# DA14682 register map
Vendor: Dialog; Series: DA14682; File version: 1.2
CPU: CM0 r1p0, little endian, MPU, FPU, 3 interrupt priority bits
Registers are 16-bit, read-write, reset 0x0 unless marked. A register's access mark holds for its fields unless they carry their own. Offsets are from the block's base; [hi:lo] are bit positions.

## CRG_TOP — CRG_TOP registers
Base 0x50000000
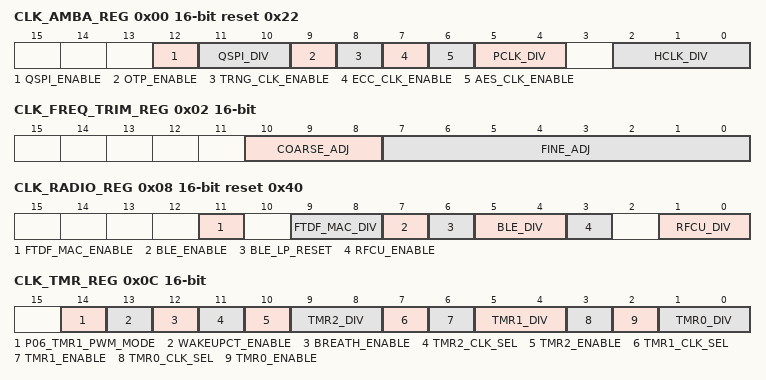
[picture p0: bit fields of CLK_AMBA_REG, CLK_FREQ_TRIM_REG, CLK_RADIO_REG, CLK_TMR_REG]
0x00 CLK_AMBA_REG reset 0x22 — HCLK, PCLK, divider and clock gates
  [12] QSPI_ENABLE — Clock enable for QSPI controller
  [11:10] QSPI_DIV — QSPI divider 00 = divide by 1 01 = divide by 2 10 = divide by 4 11 = divide by 8
  [9] OTP_ENABLE — Clock enable for OTP controller
  [8] TRNG_CLK_ENABLE — Clock enable for TRNG block
  [7] ECC_CLK_ENABLE — Clock enable for ECC block
  [6] AES_CLK_ENABLE — Clock enable for AES crypto block
  [5:4] PCLK_DIV — APB interface clock, Cascaded with HCLK: 00 = divide hclk by 1 01 = divide hclk by 2 10 = divide hclk by 4 11 = divide hclk by 8
  [2:0] HCLK_DIV — AHB interface and microprocessor clock. Source clock divided by: 000 = divide hclk by 1 001 = divide hclk by 2 010 = divide hclk by 4 011 = divide hclk by 8 1xx = divide hclk by 16
0x02 CLK_FREQ_TRIM_REG — Xtal frequency trimming register.
  [10:8] COARSE_ADJ — Xtal frequency course trimming register. 0x0 = lowest frequency 0x7 = highest frequencyIncrement or decrement the binary value with 1. Wait approximately 200usec to allow the adjustment to settle.
  [7:0] FINE_ADJ — Xtal frequency fine trimming register.0x00 = lowest frequency 0xFF = highest frequency
0x08 CLK_RADIO_REG reset 0x40 — Radio PLL control register
  [11] FTDF_MAC_ENABLE — Enable the FTDF MAC core clocks
  [9:8] FTDF_MAC_DIV — Division factor for FTCF MAC clock, relative to the DIVN clock 00 = Divide by 1 01 = Divide by 2 10 = Divide by 4 11 = Divide by 8 It should always be set to 00.
  [7] BLE_ENABLE — Enable the BLE core clocks. When the BLE system clock is disabled, either due to the CLK_RADIO_REG[BLE_ENABLE] or due to the PMU_CTRL_REG[BLE_SLEEP], then any access to the BLE Register file will issue a hard fault to the CPU.
  [6] BLE_LP_RESET — Reset for the BLE LP timer
  [5:4] BLE_DIV — Division factor for BLE core blocks, having as reference the DIVN clock: 00 = Divide by 1 01 = Divide by 2 10 = Divide by 4 11 = Divide by 8 The programmed frequency should not be lower than 8MHz, not faster than 16MHz and not faster than the programmed CPU clock frequency. Refer also to BLE_CNTL2_REG[BLE_CLK_SEL].
  [3] RFCU_ENABLE — Enable the RF control Unit clock
  [1:0] RFCU_DIV — Division factor for RF Control Unit 0x0 = divide by 1 0x1 = divide by 2 0x2 = divide by 4 0x3 = divide by 8 The programmed frequency must be exactly 8MHz.
0x0C CLK_TMR_REG — Clock control for the timers
  [14] P06_TMR1_PWM_MODE — Maps Timer1_pwm onto P06, when DEBUGGER_EN = '0'. This state is preserved during deep sleep, to allow PWM output on the pad during deep sleep.
  [13] WAKEUPCT_ENABLE — Enables the clock
  [12] BREATH_ENABLE — Enables the clock
  [11] TMR2_CLK_SEL — Selects the clock source 1 = DIV1 clock 0 = DIVN clock
  [10] TMR2_ENABLE — Enable timer clock
  [9:8] TMR2_DIV — Division factor for Timer 0x0 = divide by 1 0x1 = divide by 2 0x2 = divide by 4 0x3 = divide by 8
  [7] TMR1_CLK_SEL — Selects the clock source 1 = DIV1 clock 0 = DIVN clock
  [6] TMR1_ENABLE — Enable timer clock
  [5:4] TMR1_DIV — Division factor for Timer 0x0 = divide by 1 0x1 = divide by 2 0x2 = divide by 4 0x3 = divide by 8
  [3] TMR0_CLK_SEL — Selects the clock source 1 = DIV1 clock 0 = DIVN clock
  [2] TMR0_ENABLE — Enable timer clock
  [1:0] TMR0_DIV — Division factor for Timer 0x0 = divide by 1 0x1 = divide by 2 0x2 = divide by 4 0x3 = divide by 8
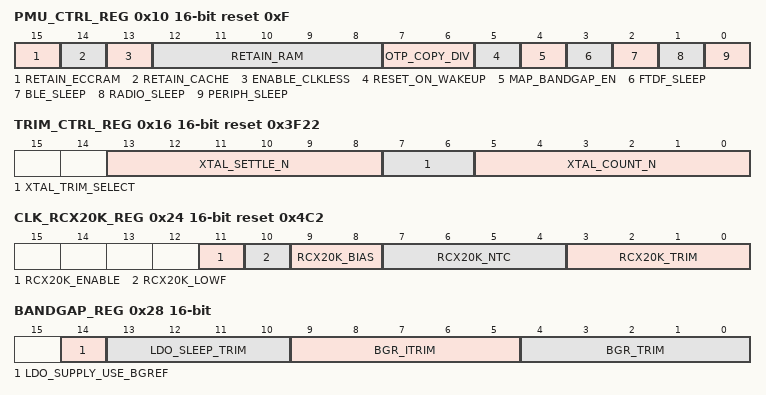
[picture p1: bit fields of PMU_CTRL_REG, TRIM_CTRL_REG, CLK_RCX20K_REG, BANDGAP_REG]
0x10 PMU_CTRL_REG reset 0xF — Power Management Unit control register
  [15] RETAIN_ECCRAM — Selects the retainability of the ECC u-Code RAM during deep sleep. '1' is retainable, '0' is power gated
  [14] RETAIN_CACHE — Selects the retainability of the cache block during deep sleep. '1' is retainable, '0' is power gated
  [13] ENABLE_CLKLESS — Selects the clockless sleep mode. Wakeup is done asynchronously. When set to '1', the lp_clk is stopped during deep sleep, until a wakeup event (not debounced) is detected by the WAKUPCT block. When set to '0', the lp_clk continues running, so the MAC counters keep on running. This mode cannot be combined with regulated sleep, so keep SLEEP_TIMER=0 when using ENABLE_CLKLESS.
  [12:8] RETAIN_RAM — Select the retainability of the 5 system memory RAM macros during deep sleep. '1' is retainable, '0' is power gated (4) is SYSRAM5 (3) is SYSRAM4 (2) is SYSRAM3 (1) is SYSRAM2 (0) is SYSRAM1
  [7:6] OTP_COPY_DIV — Sets the HCLK division during OTP mirroring
  [5] RESET_ON_WAKEUP — Perform a Hardware Reset after waking up. Booter will be started.
  [4] MAP_BANDGAP_EN — Maps the bandgap_enable to P06
  [3] FTDF_SLEEP — Put the FTDF in powerdown
  [2] BLE_SLEEP — Put the BLE in powerdown. When the BLE system clock is disabled, either due to the CLK_RADIO_REG[BLE_ENABLE] or due to the PMU_CTRL_REG[BLE_SLEEP], then any access to the BLE Register file will issue a hard fault to the CPU.
  [1] RADIO_SLEEP — Put the digital part of the radio in powerdown
  [0] PERIPH_SLEEP — Put all peripherals (I2C, UART, SPI, ADC) in powerdown
0x16 TRIM_CTRL_REG reset 0x3F22 — Control trimming of the XTAL16M
  [13:8] XTAL_SETTLE_N — Designates that the XTAL16 can be safely used as the CPU clock. When XTAL16_CLK_CNT reases this value, the signal XTAL_SETTLE_READY will be set
  [7:6] XTAL_TRIM_SELECT — Select which source controls the XTAL trimming 0b00: xtal counter. Starts XTAL16M_START_REG, after COUNT_N * 32 xtal pulses trim is changed to CLK_FREQ_TRIM_REG. 0b01: xtal OK filter. Starts with XTAL16M_START_REG, when xtal is ramping is changed to CLK_FREQ_TRIM_REG 0b10: statically forced off. Only uses CLK_FREQ_TRIM_REG. 0b11: xtal OK filter, 2 stage. Starts with XTAL16M_START_REG switches to XTAL16M_RAMP_REG when sw1='1', and switches to CLK_FREQ_TRIM_REG when sw2='1'.
  [5:0] XTAL_COUNT_N — Defines the number of XTAL cycles to be counted, before the xtal trimming is applied, in steps of 32. 0x01: 32 0x02: 64 0x3f:2016
0x24 CLK_RCX20K_REG reset 0x4C2 — RCX-oscillator control register
  [11] RCX20K_ENABLE — Enable the RCX oscillator
  [10] RCX20K_LOWF — Extra low frequency
  [9:8] RCX20K_BIAS — Bias control
  [7:4] RCX20K_NTC — Temperature control
  [3:0] RCX20K_TRIM — 0000 = lowest frequency 0111 = default 1111 = highest frequency
0x28 BANDGAP_REG — bandgap trimming
  [14] LDO_SUPPLY_USE_BGREF — 0x0 -> LDO_SUPPLY_(VBAT/USB) uses V12 voltage/(V12/2Mohm) current as reference 0x1 -> LDO_SUPPLY_(VBAT/USB) uses bandgap voltage/bandgap current (1uA) as reference -> set 0x1 in (booter-)software Switch to 0x1 at start of user application when maximum BOD functionality is switched on.
  [13:10] LDO_SLEEP_TRIM — 0x4 --> 1120 mV 0x5 --> 1089 mV 0x6 --> 1058 mV 0x7 --> 1030 mV 0x0 --> 1037 mV 0x1 --> 1005 mV 0x2 --> 978 mV 0x3 --> 946 mV 0x8 --> 952 mV 0x9 --> 918 mV 0xA --> 889 mV 0xB --> 861 mV 0xC --> 862 mV 0xD --> 828 mV 0xE --> 798 mV 0xF --> 770 mV These values are from simulation and vary over corners
  [9:5] BGR_ITRIM — Current trimming for bias
  [4:0] BGR_TRIM — Trim register for bandgap
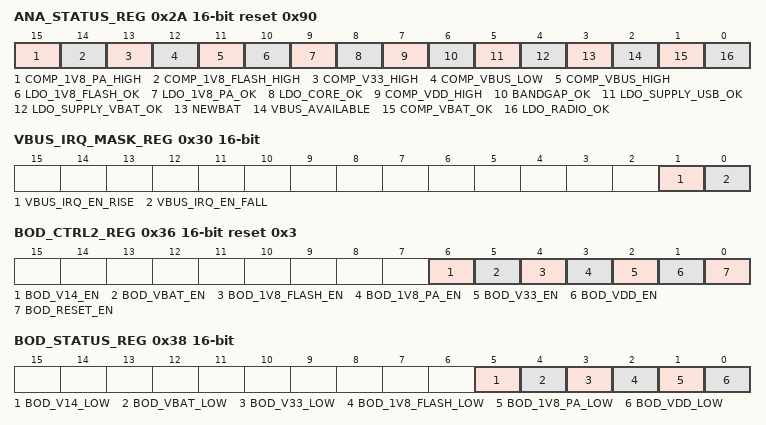
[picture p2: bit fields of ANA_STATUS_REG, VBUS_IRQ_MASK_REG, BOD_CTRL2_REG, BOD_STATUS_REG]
0x2A ANA_STATUS_REG reset 0x90 — status bit of analog (power management) circuits
  [15] COMP_1V8_PA_HIGH ro — VDD1V8P > 1.7V
  [14] COMP_1V8_FLASH_HIGH ro — VDD1V8 > 1.7V
  [13] COMP_V33_HIGH ro — V33 > 1.7V
  [12] COMP_VBUS_LOW ro — VBUS > 3.4V
  [11] COMP_VBUS_HIGH ro — VBUS > 4V
  [10] LDO_1V8_FLASH_OK ro — ldo_vdd1v8 = ok
  [9] LDO_1V8_PA_OK ro — ldo_vdd1v8P = ok
  [8] LDO_CORE_OK ro
  [7] COMP_VDD_HIGH ro — VDD > 1.13V
  [6] BANDGAP_OK ro
  [5] LDO_SUPPLY_USB_OK ro
  [4] LDO_SUPPLY_VBAT_OK ro
  [3] NEWBAT ro — new battery has been detected
  [2] VBUS_AVAILABLE ro — vbus is available (vbus > vbat)
  [1] COMP_VBAT_OK ro — vbat > 1.7V
  [0] LDO_RADIO_OK ro
0x30 VBUS_IRQ_MASK_REG — IRQ masking
  [1] VBUS_IRQ_EN_RISE — Setting this bit to '1' enables VBUS_IRQ generation when the VBUS starts to ramp above threshold
  [0] VBUS_IRQ_EN_FALL — Setting this bit to '1' enables VBUS_IRQ generation when the VBUS starts to fall below threshold
0x32 VBUS_IRQ_CLEAR_REG — Clear pending IRQ register
  [15:0] VBUS_IRQ_CLEAR wo — Writing any value to this register will reset the VBUS_IRQ line
0x36 BOD_CTRL2_REG reset 0x3 — Brown Out Detection control register
  [6] BOD_V14_EN — V14 BOD Enable
  [5] BOD_VBAT_EN — VBAT BOD Enable
  [4] BOD_1V8_FLASH_EN — 1V8 Flash BOD Enable
  [3] BOD_1V8_PA_EN — 1V8 PA BOD Enable
  [2] BOD_V33_EN — V33 BOD Enable
  [1] BOD_VDD_EN — VDD BOD Enable
  [0] BOD_RESET_EN — Generate a chip reset on BOD event
0x38 BOD_STATUS_REG — Brown Out Detection status register
  [5] BOD_V14_LOW ro — Indicates V14 > V14_Trigger
  [4] BOD_VBAT_LOW ro — Indicates VBAT > VBAT_Trigger
  [3] BOD_V33_LOW ro — Indicates V33 > V33_Trigger
  [2] BOD_1V8_FLASH_LOW ro — Indicates V18_Flash > V18_Flash_Trigger
  [1] BOD_1V8_PA_LOW ro — Indicates V18_PA > V18_PA_Trigger
  [0] BOD_VDD_LOW ro — Indicates VDD > VDD_Trigger
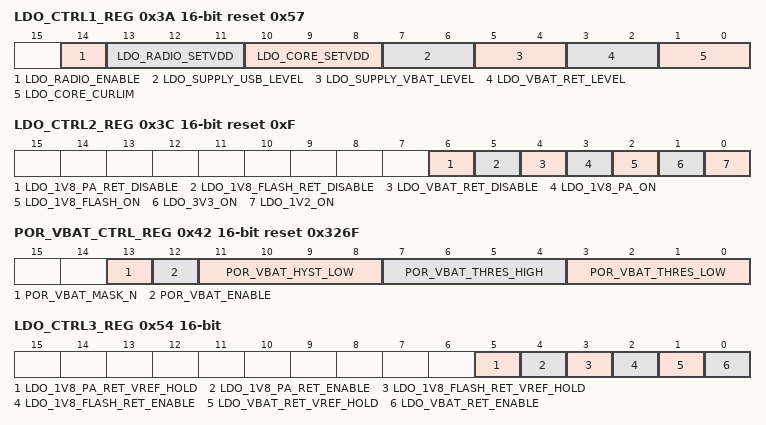
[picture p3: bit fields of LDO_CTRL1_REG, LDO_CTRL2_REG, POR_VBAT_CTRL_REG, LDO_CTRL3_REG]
0x3A LDO_CTRL1_REG reset 0x57 — LDO control register
  [14] LDO_RADIO_ENABLE — Enables (1) or disables (0) LDO_RADIO For fast XTAL startup, this bit may be kept to '1' during deep sleep. The LDO is switched off automatically when in deep sleep, and enabled when waking up.
  [13:11] LDO_RADIO_SETVDD — Sets the output voltage of LDO_RADIO 000 = 1.30 V 001 = 1.35 V 010 = 1.40 V 011 = 1.45 V 1XX = 1.50 V
  [10:8] LDO_CORE_SETVDD — Sets the output voltage of LDO_CORE 000 = 1.20 V 001 = 1.15 V 010 = 1.10 V 011 = 1.05 V 1XX = 1.32 V
  [7:6] LDO_SUPPLY_USB_LEVEL — Sets the output voltage of LDO_SUPPLY_USB 00 = 2.40 V 01 = 3.30 V 10 = 3.45 V 11 = 3.00 V
  [5:4] LDO_SUPPLY_VBAT_LEVEL — Sets the output voltage of LDO_SUPPLY_VBAT 00 = 2.40 V 01 = 3.30 V 10 = 3.45 V 11 = 3.00 V
  [3:2] LDO_VBAT_RET_LEVEL — Sets the output voltage of LDO_VBAT_RET 00 = 2.40 V 01 = 3.30 V 10 = 3.45 V 11 = 3.00 V
  [1:0] LDO_CORE_CURLIM — Sets the current limit of LDO_CORE 00 = Current limiter disabled 01 = 8 mA 10 = 60 mA 11 = 80 mA
0x3C LDO_CTRL2_REG reset 0xF — LDO control register
  [6] LDO_1V8_PA_RET_DISABLE — Disables (1) or enables (0) LDO_1V8_PA_RET
  [5] LDO_1V8_FLASH_RET_DISABLE — Disables (1) or enables (0) LDO_1V8_FLASH_RET
  [4] LDO_VBAT_RET_DISABLE — Disables (1) or enables (0) LDO_VBAT_RET
  [3] LDO_1V8_PA_ON — Enables (1) or disables (0) LDO_1V8_PA
  [2] LDO_1V8_FLASH_ON — Enables (1) or disables (0) LDO_1V8_FLASH
  [1] LDO_3V3_ON — Enables (1) or disables (0) LDO_SUPPLY_VBAT and LDO_SUPPLY_USB
  [0] LDO_1V2_ON — Enables (1) or disables (0) LDO_CORE
0x3E SLEEP_TIMER_REG — Timer for regulated sleep
  [15:0] SLEEP_TIMER — Defines the amount of ticks of the sleep clock between enabling the bandgap for re-charging the retention LDOs. This value depends on the load and should be calibrated on a per application basis.If set to 0, no recharging cycle will happen at all. Keep this value to 0 (no recharging) when using the clockless sleep.
0x42 POR_VBAT_CTRL_REG reset 0x326F — Controls the POR on VBAT
  [13] POR_VBAT_MASK_N — Enables propagation of the generated POR
  [12] POR_VBAT_ENABLE — Enables generation of the POR
  [11:8] POR_VBAT_HYST_LOW — Controls hysteresis of POR (20mV/LSB) - Set to 0x0 when non-reset settings are used for POR_VBAT_THRES_LOW and POR_VBAT_THRES_HIGH.
  [7:4] POR_VBAT_THRES_HIGH — High-side (PTAT) threshold contribution - Align setting with POR_VBAT_THRES_LOW. Set POR_VBAT_HYST_LOW to 0x0, when non-reset settings are used. Threshold --> Setting 1.25V --> 0x0 1.27V --> 0x1 1.29V --> 0x2 1.31V --> 0x3 1.44V --> 0x4 1.49V --> 0x5 1.53V --> 0x6 --> RESET 1.58V --> 0x7 1.63V --> 0x8 1.68V --> 0x9 1.73V --> 0xA 1.78V --> 0xB 1.83V --> 0xC 1.87V --> 0xD 1.92V --> 0xE 1.97V --> 0xF
  [3:0] POR_VBAT_THRES_LOW — Low-side (CTAT) threshold contribution - Align setting with POR_VBAT_THRES_HIGH. Set POR_VBAT_HYST_LOW to 0x0, when non-reset settings are used. Threshold --> Setting 1.25V --> 0xC 1.27V --> 0xC 1.29V --> 0xC 1.31V --> 0xC 1.44V --> 0x0 1.49V --> 0x1 1.53V --> 0x2 1.58V --> 0x3 1.63V --> 0x4 1.68V --> 0x5 1.73V --> 0x6 1.78V --> 0x7 1.83V --> 0x8 1.87V --> 0x9 1.92V --> 0xA 1.97V --> 0xB 1.63V -- > 0xF; Reset mode - use only with POR_VBAT_THRES_HIGH=0x6 and POR_VBAT_THRES_HYST=0x2
0x50 XTALRDY_CTRL_REG — Control register for XTALRDY IRQ
  [7:0] XTALRDY_CNT — Number of LP cycles between the crystal is enabled, and the XTALRDY_IRQ is fired. 0x00: no interrupt
0x54 LDO_CTRL3_REG — Retention LDO control register
  [5] LDO_1V8_PA_RET_VREF_HOLD — Setting of this register is "ORed" with the vref_hold control from the CRG StateMachine. "0" = CRG controls the T&H of Vref. "1" = T&H is always in "Hold"
  [4] LDO_1V8_PA_RET_ENABLE — Setting of this register is "ORed" with the ldo_enable control from the CRG StateMachine. "0" = CRG controls the enable of the LDO. "1" = LDO is always enabled To activate a retention LDO in "active-mode", this bit must be "1" and the VREF_HOLD bit must be "0".
  [3] LDO_1V8_FLASH_RET_VREF_HOLD — Setting of this register is "ORed" with the vref_hold control from the CRG StateMachine. "0" = CRG controls the T&H of Vref. "1" = T&H is always in "Hold"
  [2] LDO_1V8_FLASH_RET_ENABLE — Setting of this register is "ORed" with the ldo_enable control from the CRG StateMachine. "0" = CRG controls the enable of the LDO. "1" = LDO is always enabled To activate a retention LDO in "active-mode", this bit must be "1" and the VREF_HOLD bit must be "0".
  [1] LDO_VBAT_RET_VREF_HOLD — Setting of this register is "ORed" with the vref_hold control from the CRG StateMachine. "0" = CRG controls the T&H of Vref. "1" = T&H is always in "Hold"
  [0] LDO_VBAT_RET_ENABLE — Setting of this register is "ORed" with the ldo_enable control from the CRG StateMachine. "0" = CRG controls the enable of the LDO. "1" = LDO is always enabled To activate a retention LDO in "active-mode", this bit must be "1" and the VREF_HOLD bit must be "0".
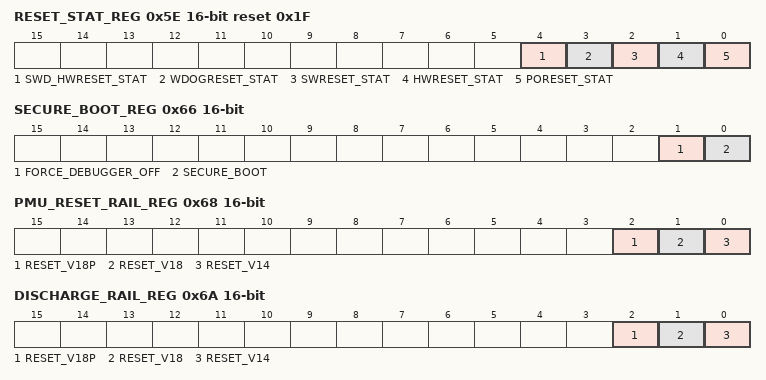
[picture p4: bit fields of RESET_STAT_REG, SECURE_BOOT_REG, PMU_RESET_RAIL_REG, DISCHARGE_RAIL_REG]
0x5E RESET_STAT_REG reset 0x1F — Reset status register
  [4] SWD_HWRESET_STAT — Indicates that a write to SWD_RESET_REG has happened. Note thatit is also set when a POReset has happened.
  [3] WDOGRESET_STAT — Indicates that a Watchdog has happened. Note that it is also set when a POReset has happened.
  [2] SWRESET_STAT — Indicates that a SW Reset has happened
  [1] HWRESET_STAT — Indicates that a HW Reset has happened
  [0] PORESET_STAT — Indicates that a PowerOn Reset has happened
0x66 SECURE_BOOT_REG — Controls secure booting
  [1] FORCE_DEBUGGER_OFF — Follows the respective OTP flag value. Is write-one-only and will be reset by POR only! Its value is updated by the BootROM code. 1: The system debugger SWD is totally disabled. 0: The system debugger is enabled with DEBUGGER_ENABLE
  [0] SECURE_BOOT — Follows the respective OTP flag value. Is write-one-only and will be reset by POR only! Its value is updated by the BootROM code. 1: system is a secure system supporting secure boot 0: system is not supporting secure boot
0x68 PMU_RESET_RAIL_REG — Controls rail resetting when RST is pulsed
  [2] RESET_V18P — 1: Enables discharging of the V18P rail when HW reset is pressed 0: this rail will not be discharged when HW reset is pressed
  [1] RESET_V18 — 1: Enables discharging of the V18 rail when HW reset is pressed 0: this rail will not be discharged when HW reset is pressed
  [0] RESET_V14 — 1: Enables discharging of the V14 rail when HW reset is pressed 0: this rail will not be discharged when HW reset is pressed
0x6A DISCHARGE_RAIL_REG — Immediate rail resetting. There is no LDO/DCDC gating
  [2] RESET_V18P — 1: Enables immediate discharging of the V18P rail. Note that the source is not disabled. 0: disable immediate discharging of the V18P rail. This bit is ORed with the automatic function controlled by PMU_RESET_RAIL_REG.RESET_V18P
  [1] RESET_V18 — 1: Enables immediate discharging of the V18 rail. Note that the source is not disabled. 0: disable immediate discharging of the V18 rail. This bit is ORed with the automatic function controlled by PMU_RESET_RAIL_REG.RESET_V18
  [0] RESET_V14 — 1: Enables immediate discharging of the V14 rail. Note that the source is not disabled. 0: disable immediate discharging of the V14 rail. This bit is ORed with the automatic function controlled by PMU_RESET_RAIL_REG.RESET_V14
